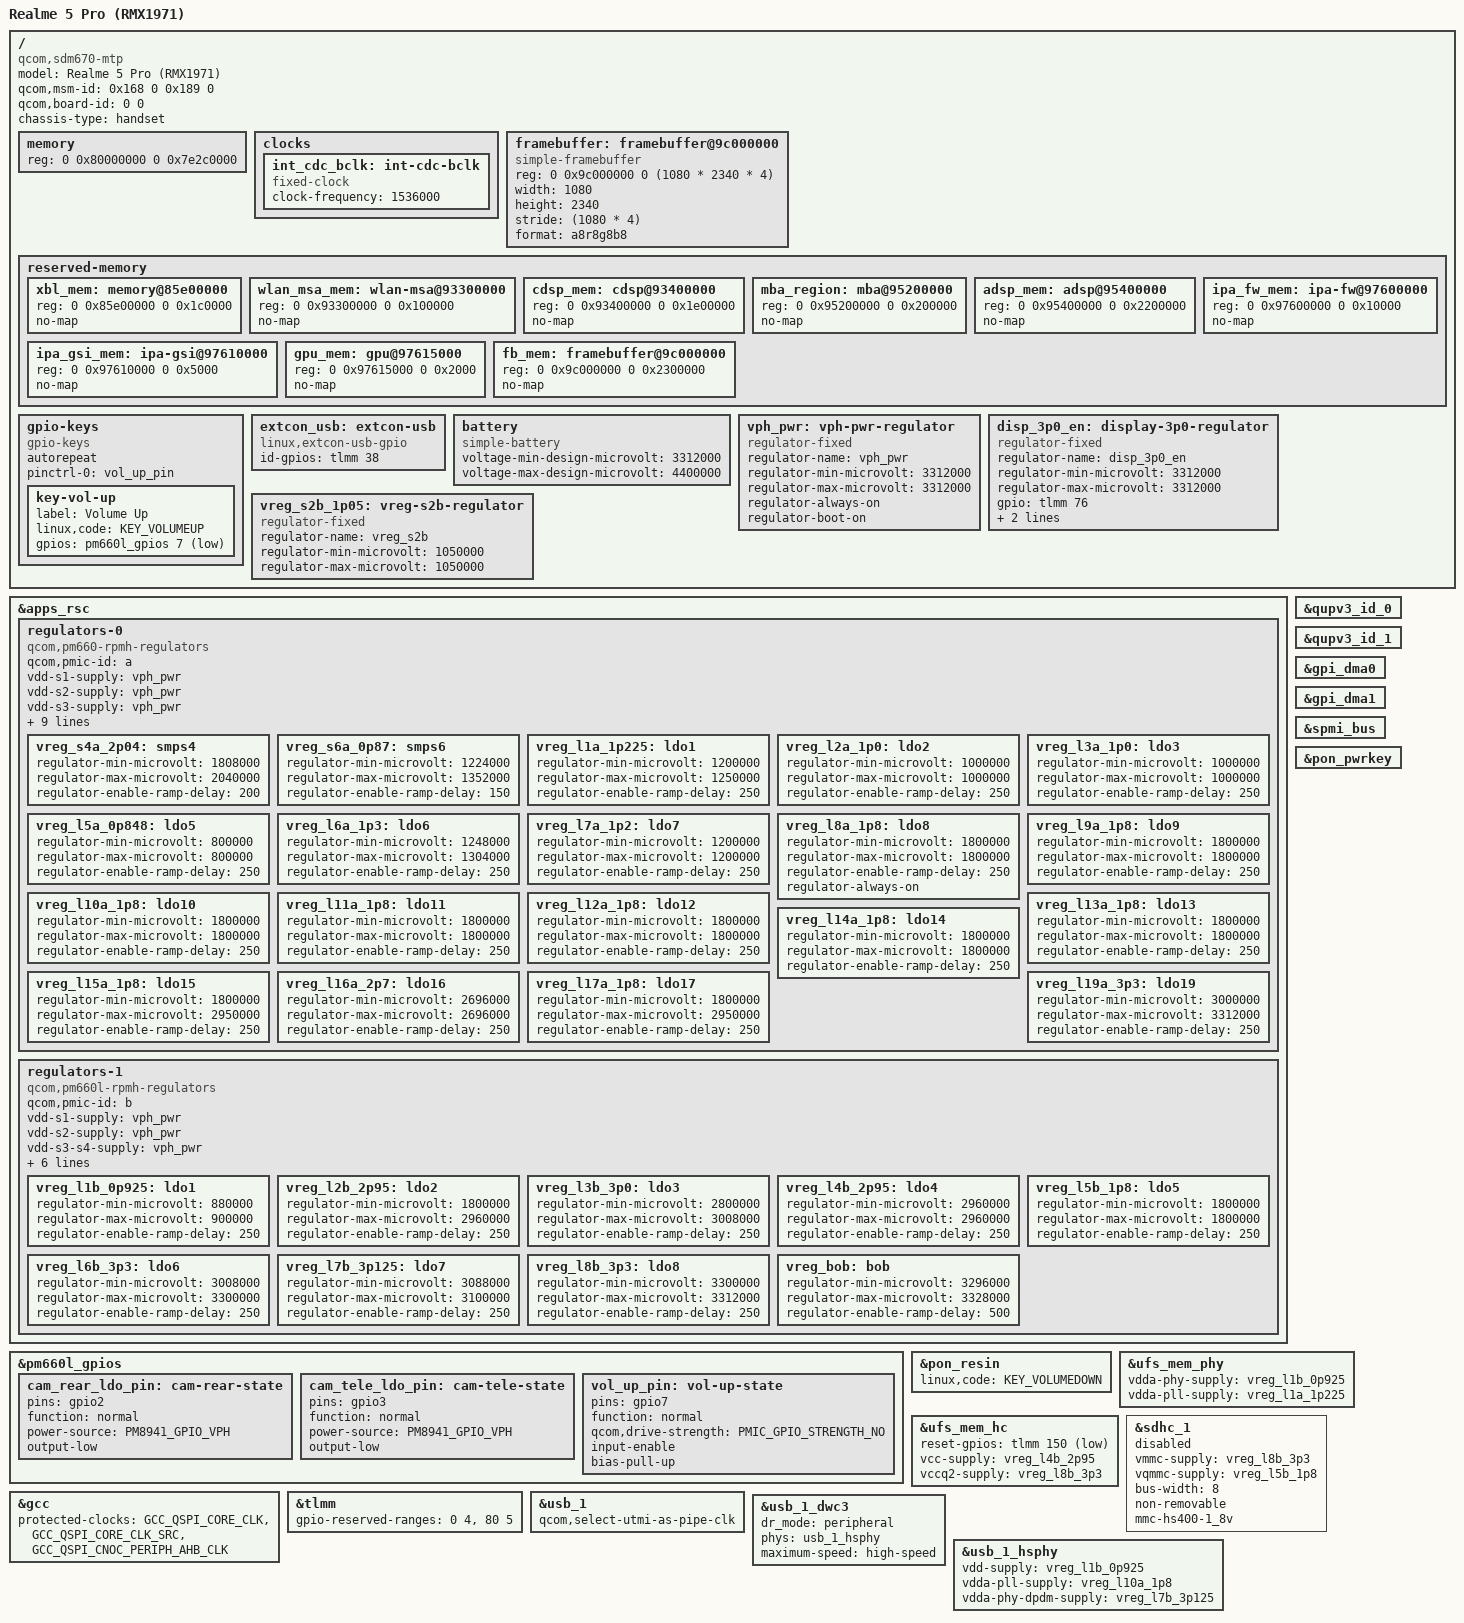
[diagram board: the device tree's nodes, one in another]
/* Realme 5 Pro (RMX1971, SM712) board description for U-Boot.
 *
 * Derived from sdm710-xiaomi-sirius.dts of 57UU/u-boot (sirius/v2.0), itself
 * ported from the postmarketOS u-boot branch that adds SDM710. Same SoC family,
 * so the PMIC, clock and reserved-memory blocks are shared; what differs is the
 * panel geometry, the storage (UFS, not eMMC) and the IDs the ABL checks.
 *
 * Identity values come from this handset's own stock DTB
 * (firmware/stock-appended-dtbs.bin, every entry: msm-id <0x168 0 0x189 0>,
 * board-id <0 0>, "Qualcomm Technologies, Inc. SDM710 SoC").
 */
// SPDX-License-Identifier: GPL-2.0

/dts-v1/;

#include <dt-bindings/gpio/gpio.h>
#include <dt-bindings/input/input.h>
#include <dt-bindings/leds/common.h>
#include <dt-bindings/pinctrl/qcom,pmic-gpio.h>
#include <dt-bindings/power/qcom-rpmpd.h>
#include "sdm710.dtsi"
#include "pm660.dtsi"
#include "pm660l.dtsi"

/*
 * sdm670.dtsi ships "memory@80000000" with reg = <0 0x80000000 0 0> and the
 * comment "we expect the bootloader to fill in the size": the node is a
 * placeholder for the ABL, which patches the DT it hands to the kernel. U-Boot
 * never sees that patched copy unless the ABL chooses to pass it, and even then
 * the path is wrong -- qcom_parse_memory() looks up the literal "/memory", not
 * "/memory@80000000", and gives up with -ENODATA on a zero size as well. The
 * replacement is a few lines below.
 */
/delete-node/ &{/memory@80000000};

/delete-node/ &xbl_mem;
/delete-node/ &wlan_msa_mem;
/delete-node/ &cdsp_mem;
/delete-node/ &mba_region;
/delete-node/ &adsp_mem;
/delete-node/ &ipa_fw_mem;
/delete-node/ &ipa_gsi_mem;
/delete-node/ &gpu_mem;

/ {
	model = "Realme 5 Pro (RMX1971)";
	compatible = "qcom,sdm670-mtp", "qcom,sdm670", "qcom,mtp";
	qcom,msm-id = <0x168 0 0x189 0>;
	qcom,board-id = <0 0>;
	chassis-type = "handset";

	/*
	 * The node must be named exactly "memory": qcom_parse_memory() reads it
	 * with fdt_path_offset(fdt, "/memory"), so "memory@80000000" would not
	 * match. Reg is read as two 64-bit cells, which is why / has
	 * #address-cells = #size-cells = 2 here.
	 *
	 * The window is the low 1.97 GiB, the same one ios-sweet hands to XNU:
	 * everything above 0x1_00000000 stays untouched, and the ABL splash
	 * buffer at 0x9c000000 sits inside it, carved out as no-map below so
	 * nothing that reads reserved-memory will hand it out.
	 */
	memory {
		device_type = "memory";
		reg = <0 0x80000000 0 0x7e2c0000>;
	};

	clocks {
		int_cdc_bclk: int-cdc-bclk {
			compatible = "fixed-clock";
			#clock-cells = <0>;
			clock-frequency = <1536000>;
		};
	};

	/*
	 * The framebuffer stays at the root, not under /chosen where the shared
	 * board trees put it. Driver model walks the children of the root node and
	 * recurses only into nodes bound as simple-bus (dm_scan_fdt_node() ->
	 * simple_bus_post_bind()), and /chosen has no driver: a framebuffer
	 * nested under it is never bound, `vidconsole` never appears, and the
	 * board runs with nowhere to print. There is no UART on a retail unit,
	 * so that would be a silent board.
	 *
	 * No chosen/stdout-path either: U-Boot reads that property as a device
	 * name, not a path, and the compiled environment already says
	 * stdout=serial,vidconsole.
	 */
	framebuffer: framebuffer@9c000000 {
		compatible = "simple-framebuffer";
		reg = <0 0x9c000000 0 (1080 * 2340 * 4)>;
		width = <1080>;
		height = <2340>;
		stride = <(1080 * 4)>;
		format = "a8r8g8b8";
		status = "okay";
	};

	reserved-memory {
		#address-cells = <2>;
		#size-cells = <2>;

		xbl_mem: memory@85e00000 {
			reg = <0 0x85e00000 0 0x1c0000>;
			no-map;
		};

		wlan_msa_mem: wlan-msa@93300000 {
			reg = <0 0x93300000 0 0x100000>;
			no-map;
		};

		cdsp_mem: cdsp@93400000 {
			reg = <0 0x93400000 0 0x1e00000>;
			no-map;
		};

		mba_region: mba@95200000 {
			reg = <0 0x95200000 0 0x200000>;
			no-map;
		};

		adsp_mem: adsp@95400000 {
			reg = <0 0x95400000 0 0x2200000>;
			no-map;
		};

		ipa_fw_mem: ipa-fw@97600000 {
			reg = <0 0x97600000 0 0x10000>;
			no-map;
		};

		ipa_gsi_mem: ipa-gsi@97610000 {
			reg = <0 0x97610000 0 0x5000>;
			no-map;
		};

		gpu_mem: gpu@97615000 {
			reg = <0 0x97615000 0 0x2000>;
			no-map;
		};

		fb_mem: framebuffer@9c000000 {
			reg = <0 0x9c000000 0 0x2300000>;
			no-map;
		};
	};

	gpio-keys {
		compatible = "gpio-keys";
		autorepeat;

		pinctrl-names = "default";
		pinctrl-0 = <&vol_up_pin>;

		key-vol-up {
			label = "Volume Up";
			linux,code = <KEY_VOLUMEUP>;
			gpios = <&pm660l_gpios 7 GPIO_ACTIVE_LOW>;
		};
	};

	extcon_usb: extcon-usb {
		compatible = "linux,extcon-usb-gpio";
		id-gpios = <&tlmm 38 GPIO_ACTIVE_HIGH>;
	};

	battery: battery {
		compatible = "simple-battery";
		voltage-min-design-microvolt = <3312000>;
		voltage-max-design-microvolt = <4400000>;
	};

	/* Regulators */
	vph_pwr: vph-pwr-regulator {
		compatible = "regulator-fixed";
		regulator-name = "vph_pwr";
		regulator-min-microvolt = <3312000>;
		regulator-max-microvolt = <3312000>;
		regulator-always-on;
		regulator-boot-on;
	};

	disp_3p0_en: display-3p0-regulator {
		compatible = "regulator-fixed";
		regulator-name = "disp_3p0_en";
		regulator-min-microvolt = <3312000>;
		regulator-max-microvolt = <3312000>;
		gpio = <&tlmm 76 GPIO_ACTIVE_HIGH>;
		enable-active-high;
		regulator-boot-on;
	};

	vreg_s2b_1p05: vreg-s2b-regulator {
		compatible = "regulator-fixed";
		regulator-name = "vreg_s2b";
		regulator-min-microvolt = <1050000>;
		regulator-max-microvolt = <1050000>;
	};
};

/* Regulators */
&apps_rsc {
	regulators-0 {
		compatible = "qcom,pm660-rpmh-regulators";
		qcom,pmic-id = "a";

		vdd-s1-supply = <&vph_pwr>;
		vdd-s2-supply = <&vph_pwr>;
		vdd-s3-supply = <&vph_pwr>;
		vdd-s4-supply = <&vph_pwr>;
		vdd-s5-supply = <&vph_pwr>;
		vdd-s6-supply = <&vph_pwr>;

		vdd-l1-l6-l7-supply = <&vreg_s6a_0p87>;
		vdd-l2-l3-supply = <&vreg_s2b_1p05>;
		vdd-l5-supply = <&vreg_s2b_1p05>;
		vdd-l8-l9-l10-l11-l12-l13-l14-supply = <&vreg_s4a_2p04>;
		vdd-l15-l16-l17-l18-l19-supply = <&vreg_bob>;

		/*
		 * S1A (FTAPC0), S2A (FTAPC1), S3A (HFAPC1) are managed
		 * by the Core Power Reduction hardened (CPRh) and the
		 * Operating State Manager (OSM) HW automatically.
		 */

		vreg_s4a_2p04: smps4 {
			regulator-min-microvolt = <1808000>;
			regulator-max-microvolt = <2040000>;
			regulator-enable-ramp-delay = <200>;
		};

		vreg_s6a_0p87: smps6 {
			regulator-min-microvolt = <1224000>;
			regulator-max-microvolt = <1352000>;
			regulator-enable-ramp-delay = <150>;
		};

		/* LDOs */
		vreg_l1a_1p225: ldo1 {
			regulator-min-microvolt = <1200000>;
			regulator-max-microvolt = <1250000>;
			regulator-enable-ramp-delay = <250>;
		};

		vreg_l2a_1p0: ldo2 {
			regulator-min-microvolt = <1000000>;
			regulator-max-microvolt = <1000000>;
			regulator-enable-ramp-delay = <250>;
		};

		vreg_l3a_1p0: ldo3 {
			regulator-min-microvolt = <1000000>;
			regulator-max-microvolt = <1000000>;
			regulator-enable-ramp-delay = <250>;
		};

		/* Possibly unused according to stock (dumped) DT... */
		vreg_l5a_0p848: ldo5 {
			regulator-min-microvolt = <800000>;
			regulator-max-microvolt = <800000>;
			regulator-enable-ramp-delay = <250>;
		};

		vreg_l6a_1p3: ldo6 {
			regulator-min-microvolt = <1248000>;
			regulator-max-microvolt = <1304000>;
			regulator-enable-ramp-delay = <250>;
		};

		vreg_l7a_1p2: ldo7 {
			regulator-min-microvolt = <1200000>;
			regulator-max-microvolt = <1200000>;
			regulator-enable-ramp-delay = <250>;
		};

		vreg_l8a_1p8: ldo8 {
			regulator-min-microvolt = <1800000>;
			regulator-max-microvolt = <1800000>;
			regulator-enable-ramp-delay = <250>;
			regulator-always-on;
		};

		vreg_l9a_1p8: ldo9 {
			regulator-min-microvolt = <1800000>;
			regulator-max-microvolt = <1800000>;
			regulator-enable-ramp-delay = <250>;
		};

		vreg_l10a_1p8: ldo10 {
			regulator-min-microvolt = <1800000>;
			regulator-max-microvolt = <1800000>;
			regulator-enable-ramp-delay = <250>;
		};

		vreg_l11a_1p8: ldo11 {
			regulator-min-microvolt = <1800000>;
			regulator-max-microvolt = <1800000>;
			regulator-enable-ramp-delay = <250>;
		};

		vreg_l12a_1p8: ldo12 {
			regulator-min-microvolt = <1800000>;
			regulator-max-microvolt = <1800000>;
			regulator-enable-ramp-delay = <250>;
		};

		vreg_l13a_1p8: ldo13 {
			regulator-min-microvolt = <1800000>;
			regulator-max-microvolt = <1800000>;
			regulator-enable-ramp-delay = <250>;
		};

		vreg_l14a_1p8: ldo14 {
			regulator-min-microvolt = <1800000>;
			regulator-max-microvolt = <1800000>;
			regulator-enable-ramp-delay = <250>;
		};

		vreg_l15a_1p8: ldo15 {
			regulator-min-microvolt = <1800000>;
			regulator-max-microvolt = <2950000>;
			regulator-enable-ramp-delay = <250>;
		};

		// Stock sets it to 2700000, but range seems unsupported...
		vreg_l16a_2p7: ldo16 {
			regulator-min-microvolt = <2696000>;
			regulator-max-microvolt = <2696000>;
			regulator-enable-ramp-delay = <250>;
		};

		vreg_l17a_1p8: ldo17 {
			regulator-min-microvolt = <1800000>;
			regulator-max-microvolt = <2950000>;
			regulator-enable-ramp-delay = <250>;
		};

		vreg_l19a_3p3: ldo19 {
			regulator-min-microvolt = <3000000>;
			regulator-max-microvolt = <3312000>;
			regulator-enable-ramp-delay = <250>;
		};
	};

	regulators-1 {
		compatible = "qcom,pm660l-rpmh-regulators";
		qcom,pmic-id = "b";

		vdd-s1-supply = <&vph_pwr>;
		vdd-s2-supply = <&vph_pwr>;
		vdd-s3-s4-supply = <&vph_pwr>;
		vdd-s5-supply = <&vph_pwr>;

		vdd-l1-l9-l10-supply = <&vreg_s2b_1p05>;
		vdd-l2-supply = <&vreg_bob>;
		vdd-l3-l5-l7-l8-supply = <&vreg_bob>;
		vdd-l4-l6-supply = <&vreg_bob>;
		vdd-bob-supply = <&vph_pwr>;

		/* LDOs */
		vreg_l1b_0p925: ldo1 {
			regulator-min-microvolt = <880000>;
			regulator-max-microvolt = <900000>;
			regulator-enable-ramp-delay = <250>;
		};

		vreg_l2b_2p95: ldo2 {
			regulator-min-microvolt = <1800000>;
			regulator-max-microvolt = <2960000>;
			regulator-enable-ramp-delay = <250>;
		};

		vreg_l3b_3p0: ldo3 {
			regulator-min-microvolt = <2800000>;
			regulator-max-microvolt = <3008000>;
			regulator-enable-ramp-delay = <250>;
		};

		vreg_l4b_2p95: ldo4 {
			regulator-min-microvolt = <2960000>;
			regulator-max-microvolt = <2960000>;
			regulator-enable-ramp-delay = <250>;
		};

		vreg_l5b_1p8: ldo5 {
			regulator-min-microvolt = <1800000>;
			regulator-max-microvolt = <1800000>;
			regulator-enable-ramp-delay = <250>;
		};

		vreg_l6b_3p3: ldo6 {
			regulator-min-microvolt = <3008000>;
			regulator-max-microvolt = <3300000>;
			regulator-enable-ramp-delay = <250>;
		};

		vreg_l7b_3p125: ldo7 {
			regulator-min-microvolt = <3088000>;
			regulator-max-microvolt = <3100000>;
			regulator-enable-ramp-delay = <250>;
		};

		vreg_l8b_3p3: ldo8 {
			regulator-min-microvolt = <3300000>;
			regulator-max-microvolt = <3312000>;
			regulator-enable-ramp-delay = <250>;
		};

		/*
		 * Downstream specifies a fixed voltage of 3.312 V, but the
		 * PMIC4 BOB ranges don't support that. Widen the range a
		 * little to avoid adding a new BOB regulator type.
		 */
		vreg_bob: bob {
			regulator-min-microvolt = <3296000>;
			regulator-max-microvolt = <3328000>;
			regulator-enable-ramp-delay = <500>;
		};
	};
};

/* Enable i2c/spi blocks */
&qupv3_id_0 {
	status = "okay";
};

&qupv3_id_1 {
	status = "okay";
};

&gpi_dma0 {
	status = "okay";
};

&gpi_dma1 {
	status = "okay";
};

&spmi_bus {
	status = "okay";
};

&pm660l_gpios {
	cam_rear_ldo_pin: cam-rear-state {
		pins = "gpio2";
		function = "normal";
		power-source = <PM8941_GPIO_VPH>;
		output-low;
	};

	cam_tele_ldo_pin: cam-tele-state {
		pins = "gpio3";
		function = "normal";
		power-source = <PM8941_GPIO_VPH>;
		output-low;
	};

	vol_up_pin: vol-up-state {
		pins = "gpio7";
		function = "normal";
		qcom,drive-strength = <PMIC_GPIO_STRENGTH_NO>;
		input-enable;
		bias-pull-up;
	};
};

&pon_pwrkey {
	status = "okay";
};

&pon_resin {
	linux,code = <KEY_VOLUMEDOWN>;
	status = "okay";
};

/* Storage: UFS on 0x1d84000 (RMX1971 has no eMMC; the ABL left it powered) */
&ufs_mem_phy {
	status = "okay";

	vdda-phy-supply = <&vreg_l1b_0p925>;
	vdda-pll-supply = <&vreg_l1a_1p225>;
};

&ufs_mem_hc {
	status = "okay";

	reset-gpios = <&tlmm 150 GPIO_ACTIVE_LOW>;

	vcc-supply = <&vreg_l4b_2p95>;
	vccq2-supply = <&vreg_l8b_3p3>;
};

/* No eMMC on RMX1971 */
&sdhc_1 {
	status = "disabled";

	vmmc-supply = <&vreg_l8b_3p3>;
	vqmmc-supply = <&vreg_l5b_1p8>;

	bus-width = <8>;
	non-removable;

	mmc-hs400-1_8v;
};
/* No MicroSD slot on RMX1971; SDHC_2 stays disabled. */

/* Global Clock Controller */
&gcc {
	protected-clocks = <GCC_QSPI_CORE_CLK>,
		<GCC_QSPI_CORE_CLK_SRC>,
		<GCC_QSPI_CNOC_PERIPH_AHB_CLK>;
};

/* SoC GPIO aka pinctrl */
&tlmm {
	gpio-reserved-ranges = <0 4>, <80 5>;
};

/* USB: Only USB2.0 because Xiaomi are cheapskates */
&usb_1 {
	status = "okay";
	qcom,select-utmi-as-pipe-clk;
};

&usb_1_dwc3 {
	dr_mode = "peripheral";
	phys = <&usb_1_hsphy>;
	phy-names = "usb2-phy";
	maximum-speed = "high-speed";
};

&usb_1_hsphy {
	status = "okay";
	vdd-supply = <&vreg_l1b_0p925>;
	vdda-pll-supply = <&vreg_l10a_1p8>;
	vdda-phy-dpdm-supply = <&vreg_l7b_3p125>;
};
